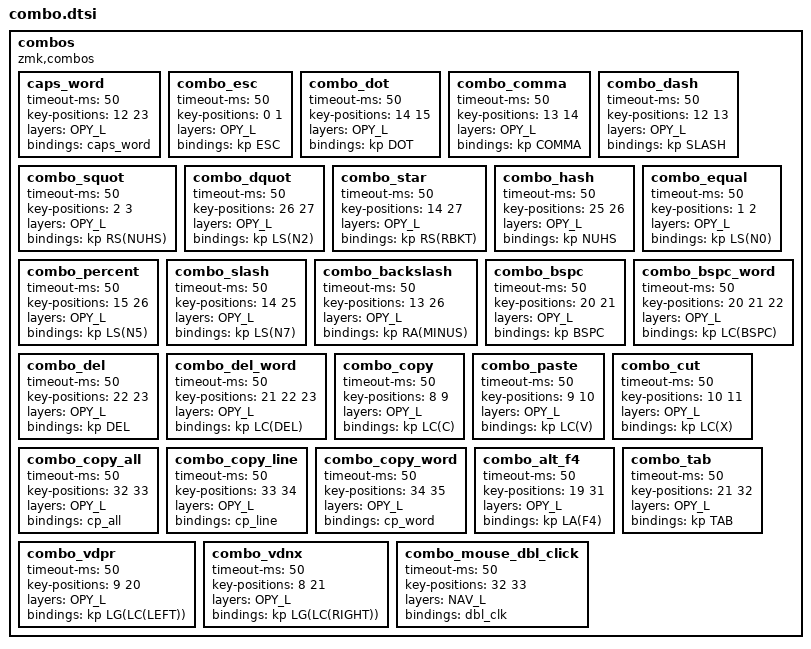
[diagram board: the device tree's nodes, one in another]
/*                KEY POSITIONS

  ╭─────────────────────────────────────────────────╮
  │  0   1   2   3   4 │  5  6 │  7   8   9  10  11 │
  │ 12  13  14  15  16 │ 17 18 │ 19  20  21  22  23 │
  │ 24  25  26  27  28 │ 29 30 │ 31  32  33  34  35 │
  │ 36  37  38  39 │  40   │   41  │ 42  43  44  45 │
  ╰─────────────────────────────────────────────────╯
*/

    combos {
        compatible = "zmk,combos";
        // Both sides
        caps_word {
            timeout-ms = <50>;
            key-positions = <12 23>;
            layers = <OPY_L>;
            bindings = <&caps_word>;
        };
        // Left side
        combo_esc {
            timeout-ms = <50>;
            key-positions = <0 1>;
            layers = <OPY_L>;
            bindings = <&kp ESC>;
        };
        combo_dot {
            timeout-ms = <50>;
            key-positions = <14 15>;
             layers = <OPY_L>;
            bindings = <&kp DOT>;
        };
        combo_comma {
            timeout-ms = <50>;
            key-positions = <13 14>;
             layers = <OPY_L>;
            bindings = <&kp COMMA>;
        };
        combo_dash {
            timeout-ms = <50>;
            key-positions = <12 13>;
             layers = <OPY_L>;
            bindings = <&kp SLASH>;
        };
        combo_squot {
            timeout-ms = <50>;
            key-positions = <2 3>;
             layers = <OPY_L>;
            bindings = <&kp RS(NUHS)>;
        };
        combo_dquot {
            timeout-ms = <50>;
            key-positions = <26 27>;
             layers = <OPY_L>;
            bindings = <&kp LS(N2)>;
        };
        combo_star {
            timeout-ms = <50>;
            key-positions = <14 27>;
             layers = <OPY_L>;
            bindings = <&kp RS(RBKT)>;
        };
        combo_hash {
            timeout-ms = <50>;
            key-positions = <25 26>;
             layers = <OPY_L>;
            bindings = <&kp NUHS>;
        };
        combo_equal {
            timeout-ms = <50>;
            key-positions = <1 2>;
             layers = <OPY_L>;
            bindings = <&kp LS(N0)>;
        };
        combo_percent {
            timeout-ms = <50>;
            key-positions = <15 26>;
             layers = <OPY_L>;
            bindings = <&kp LS(N5)>;
        };
        combo_slash {
            timeout-ms = <50>;
            key-positions = <14 25>;
             layers = <OPY_L>;
            bindings = <&kp LS(N7)>;
        };
        combo_backslash {
            timeout-ms = <50>;
            key-positions = <13 26>;
             layers = <OPY_L>;
            bindings = <&kp RA(MINUS)>;
        };
        // Right side
        combo_bspc {
            timeout-ms = <50>;
            key-positions = <20 21>;
             layers = <OPY_L>;
            bindings = <&kp BSPC>;
        };
        combo_bspc_word {
            timeout-ms = <50>;
            key-positions = <20 21 22>;
            layers = <OPY_L>;
            bindings = <&kp LC(BSPC)>;
        };
        combo_del {
            timeout-ms = <50>;
            key-positions = <22 23>;
            layers = <OPY_L>;
            bindings = <&kp DEL>;
        };
        combo_del_word {
            timeout-ms = <50>;
            key-positions = <21 22 23>;
            layers = <OPY_L>;
            bindings = <&kp LC(DEL)>;
        };
        combo_copy {
            timeout-ms = <50>;
            key-positions = <8 9>;
             layers = <OPY_L>;
            bindings = <&kp LC(C)>;
        }; 
        combo_paste {
            timeout-ms = <50>;
            key-positions = <9 10>;
             layers = <OPY_L>;
            bindings = <&kp LC(V)>;
        };
        combo_cut {
            timeout-ms = <50>;
            key-positions = <10 11>;
             layers = <OPY_L>;
            bindings = <&kp LC(X)>;
        };
        combo_copy_all {
            timeout-ms = <50>;
            key-positions = <32 33>;
            layers = <OPY_L>;
            bindings = <&cp_all>;
        };
        combo_copy_line {
            timeout-ms = <50>;
            key-positions = <33 34>;
            layers = <OPY_L>;
            bindings = <&cp_line>;
        };
        combo_copy_word {
            timeout-ms = <50>;
            key-positions = <34 35>;
            layers = <OPY_L>;
            bindings = <&cp_word>;
        };
        combo_alt_f4 {
            timeout-ms = <50>;
            key-positions = <19 31>;
            layers = <OPY_L>;
            bindings = <&kp LA(F4)>;
        };
        combo_tab {
            timeout-ms = <50>;
            key-positions = <21 32>;
            layers = <OPY_L>;
            bindings = <&kp TAB>;
        };
        combo_vdpr {
            timeout-ms = <50>;
            key-positions = <9 20>;
            layers = <OPY_L>;
            bindings = <&kp LG(LC(LEFT))>;
        };
        combo_vdnx {
            timeout-ms = <50>;
            key-positions = <8 21>;
            layers = <OPY_L>;
            bindings = <&kp LG(LC(RIGHT))>;
        };
        combo_mouse_dbl_click {
            timeout-ms = <50>;
            key-positions = <32 33>;
            layers = <NAV_L>;
            bindings = <&dbl_clk>;
        };
        // combos task previous, task next hinzufügen
    };
